# CY8C5888LTI_LP097 register map
File version: 0.1
CY8C58LP
Registers are 8-bit, read-write, no defined reset value unless marked. A register's access mark holds for its fields unless they carry their own. Offsets are from the block's base; lines under a group give offsets from that group; [hi:lo] are bit positions; {n}, {i} and the like mark numbered series; 'fields as' and 'values as' point back to an identical list; <NAME> marks a mode.

## Memory map
0x00000000 LCD_Seg_1
0x00000000 Opamp_1
0x00000000 Timer_1
0x00000000 VDAC8_1
0x00000000 Comp_1
0x00000000 PGA_1

## LCD_Seg_1
Base 0x00000000
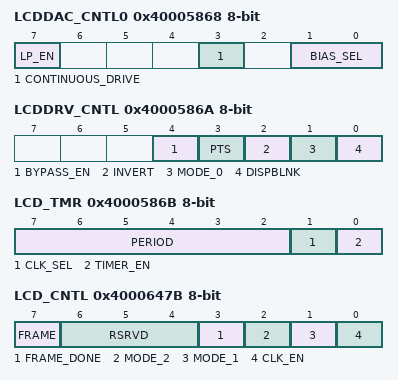
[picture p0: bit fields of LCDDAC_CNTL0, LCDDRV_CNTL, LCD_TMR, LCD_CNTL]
0x40005868 LCDDAC_CNTL0 — LCD DAC Control Register 0
  [7] LP_EN — Allows the UDB to gate the Low Power Ack signal
    0=UDB_LP_ACK_DISABLED (LCD subsystem LP ack is directly driven by the lpreq from thepower manager); 1=UDB_LP_ACK_ENABLED (UDB will gate the Low Power Ack for the LCD Subsystem)
  [3] CONTINUOUS_DRIVE — Allows the LCDDAC to remain active when the chip goes to sleep
    0=LCDDAC_INACTIVE (LCDDAC is powered down when the chip is in sleep); 1=LCDDAC_ACTIVE (LCDDAC is active when the chip is in sleep)
  [1:0] BIAS_SEL — Selects the LCD bias multiplex ratio
    0=Cy1DIV3_BIAS (1DIV3 BIAS); 1=Cy1DIV4_BIAS (1DIV4 BIAS)
0x40005869 LCDDAC_CNTL1 — LCD DAC Control Register 1
  [5:0] LP_EN — LCD Contrast control setting
0x4000586A LCDDRV_CNTL — LCD Driver Control Register
  [4] BYPASS_EN — This bit enables bypassing the LCD Driver, so that the LCDDAC is driving the LCD glass
    0=LCD_BYPASS_EN_LCD_DRV_DRIVES_GLASS (Normal mode); 1=LCD_BYPASS_EN_LCD_DAC_DRIVES_GLASS (Bypass mode)
  [3] PTS — Signal enables the LCD Driver to be able to drive to supply level
  [2] INVERT — Invert LCD Display
    0=LCD_INVERT_DISABLED (Normal display); 1=LCD_INVERT_ENABLED (Inverted display)
  [1] MODE_0 — LSB of LCD Driver mode[2..0]
  [0] DISPBLNK — Allows the LCDDAC to remain active when the chip goes to sleep
    0=LCD_DISPBLNK_HIZ (When in a low power mode, set output buffer in LCD Drivers to hi impedance); 1=LCD_DISPBLNK_BLANK (When in a low power mode, set output buffer in LCD Drivers to ground)
0x4000586B LCD_TMR — LCD Timer Register
  [7:2] PERIOD — LCD timer period
  [1] CLK_SEL — LCD timer clock source selection bit
    0=LCD_CLK_SEL_ILO_1K (ILO 1K); 1=LCD_CLK_SEL_ONEPPS (OPPS from 32k External Watch Crystal)
  [0] TIMER_EN — LCD timer enable bit
    0=LCD_TIMER_DISABLED (Timer is disabled); 1=LCD_TIMER_ENABLED (Timer is enabled)
{0x40005B50+i} LCDDAC_SW{i} (i=0..4) — LCD DAC Switch Register {i}
  [2:0] SW0 — Switch Control for LCD_BIAS_BUS[{i}]
0x4000647B LCD_CNTL — LCD Control Register
  [7] FRAME — Generates Frame signal for LCD Driver
  [6:4] RSRVD ro — Reserved
  [3] FRAME_DONE ro — Generates a synchronous pulse after completion of DMA Frame transaction
  [2] MODE_2 — MSB of LCD Driver mode[2..0]
  [1] MODE_1 — Bit 1 of LCD Driver mode[2..0]
  [0] CLK_EN — This bit enables the LCD component operation
    0=LCD_CLK_DISABLED (LCD UDB clock is disabled); 1=LCD_CLK_ENABLED (LCD UDB clock is disabled)

## Opamp_1
Base 0x00000000
0x400043A4 PM_ACT_CFG4 — Active Power Mode Configuration Register 4
  [3:0] EN_OPAMP — Enables subsystems during active power mode
    0=Blk_0 (Enables analog linear output buffer for Opamp block 0); 2=Blk_1 (Enables analog linear output buffer for Opamp block 1); 4=Blk_2 (Enables analog linear output buffer for Opamp block 2); 8=Blk_3 (Enables analog linear output buffer for Opamp block 3)
0x400043B4 PM_STBY_CFG4 — Standby Power Mode Configuration Register 4
  [3:0] EN_OPAMP — Enables subsystems during standby power mode
    values as PM_ACT_CFG4.EN_OPAMP
0x40004626 OPAMP__TR0 — Analog Output Buffer Trim Register 0
  [4:0] offset_trim — Offset Trim: 420uV typical step size; +/- 6.8mV offset trimmable range
0x40004627 OPAMP__TR1 — Analog Output Buffer Trim Register 1
0x4000585E OPAMP__CR — Analog Output Buffer Configuration Register
  [1:0] pwr_mode — Power Mode
    0=Default_Fast (Default Power mode Fast); 1=Slow (Power Mode Slow); 2=Medium (Power Mode Medium); 3=Fast (Power Mode Fast)
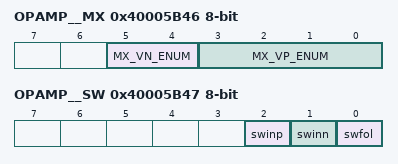
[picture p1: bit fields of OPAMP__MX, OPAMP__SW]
0x40005B46 OPAMP__MX — Analog Buffer Input Selection Register
  [5:4] MX_VN_ENUM — MUX select VN (Negative terminal input)
    0=OPAMP0_MX_VN_DEFAULT (Default - Not Connected (NC)); 1=OPAMP0_MX_VN_AG4 (MUX Selection AGL(4)); 2=OPAMP0_MX_VN_AG6 (MUX Selection AGL(6)); 3=OPAMP0_MX_VN_0x3 (Reserved (NC))
  [3:0] MX_VP_ENUM — MUX select VP (Positive terminal input)
    0=OPAMP0_MX_VP_DEFAULT (Default - Not Connected (NC)); {v}=OPAMP0_MX_VP_AG{v+3} (MUX Selection AGL({v+3})) (v=1..4); {v}=OPAMP0_MX_VP_ABUS{v-5} (MUX Selection ABUSL({v-5})) (v=5..8); 9=OPAMP0_MX_VP_VREF (MUX Selection: OPAMP Voltage Reference); {v}=OPAMP0_MX_VP_H_{0x0+v} (Reserved (NC)) (v=10..15)
0x40005B47 OPAMP__SW — Analog Buffer Routing Switch Register
  [2] swinp — Switch Enable Positive Input
  [1] swinn — Switch Enable Negative Input
  [0] swfol — Switch Enable Follow
